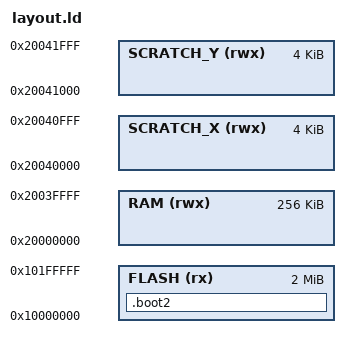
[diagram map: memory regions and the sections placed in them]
MEMORY {
    FLASH(rx) : ORIGIN = 0x10000000, LENGTH = 2048k
    RAM(rwx) : ORIGIN =  0x20000000, LENGTH = 256k
    SCRATCH_X(rwx) : ORIGIN = 0x20040000, LENGTH = 4k
    SCRATCH_Y(rwx) : ORIGIN = 0x20041000, LENGTH = 4k
}

ENTRY (_boot2)

SECTIONS {
    /* Beginning of flash has the secondary loader, exactly 256 */
    .boot2 : {
        __boot2_start__ = .;
        KEEP (*(.boot2))
        __boot2_end__ = .;
    } > FLASH
    ASSERT(__boot2_end__ - __boot2_start__ <= 256,
        "ERROR: Pico second stage bootloader must be at most 256 bytes in size")

}
